# APM32F072 register map
File version: 1.0
Registers are 32-bit, read-write, reset 0x0 unless marked. A register's access mark holds for its fields unless they carry their own. Offsets are from the block's base; [hi:lo] are bit positions; {n}, {i} and the like mark numbered series.

## GPIOF — General-purpose I/Os
Base 0x48001400
Same registers: GPIOB 0x48000400, GPIOC 0x48000800, GPIOD 0x48000C00, GPIOE 0x48001000
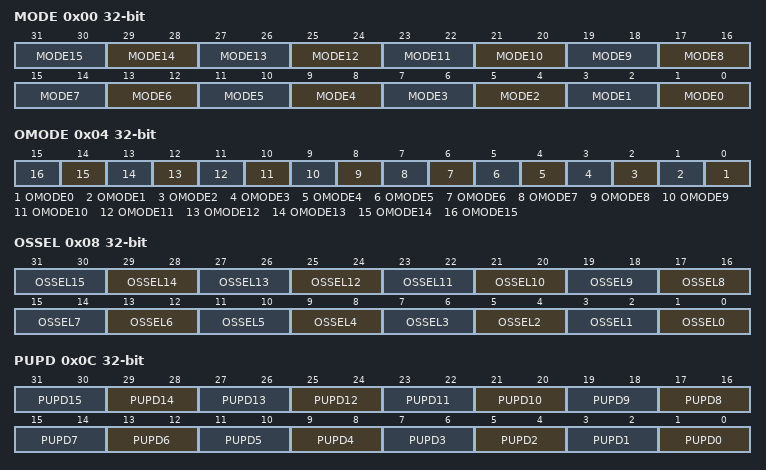
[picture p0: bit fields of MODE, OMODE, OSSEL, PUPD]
0x00 MODE — GPIO port mode register
  [2n+1:2n] MODE{n} (n=0..15) — Port x configuration bits (y = 0..15)
0x04 OMODE — GPIO port output type register
  [n] OMODE{n} (n=0..15) — Port x configuration bit {n}
0x08 OSSEL — GPIO port output speed register
  [2n+1:2n] OSSEL{n} (n=0..15) — Port x configuration bits (y = 0..15)
0x0C PUPD — GPIO port pull-up/pull-down register
  [2n+1:2n] PUPD{n} (n=0..15) — Port x configuration bits (y = 0..15)
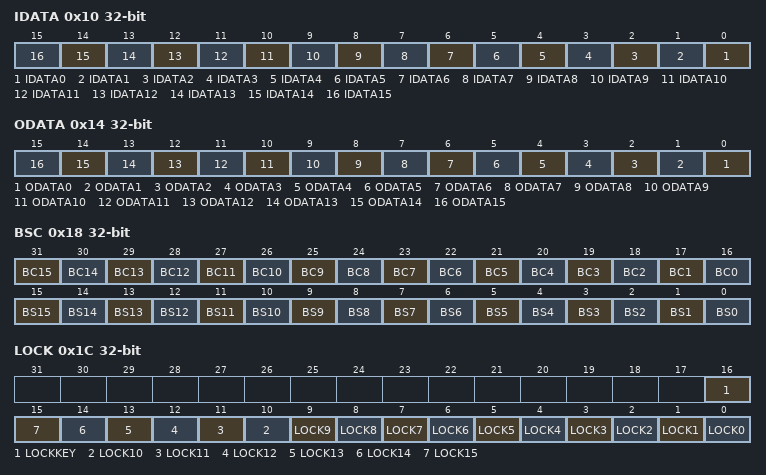
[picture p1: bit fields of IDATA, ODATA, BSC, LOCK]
0x10 IDATA ro — GPIO port input data register
  [n] IDATA{n} (n=0..15) — Port input data (y = 0..15)
0x14 ODATA — GPIO port output data register
  [n] ODATA{n} (n=0..15) — Port output data (y = 0..15)
0x18 BSC wo — GPIO port bit set/clear register
  [n+16] BC{n} (n=1..15) — Port x clear bit y (y = 0..15)
  [16] BC0 — Port x set bit y ( y = 0..15)
  [n] BS{n} (n=9..15) — Port x set bit y ( y = 0..15)
  [n] BS{n} (n=0..8) — Port x set bit y (y = 0..15)
0x1C LOCK — GPIO port configuration lock register
  [16] LOCKKEY — Port x lock bit y
  [n] LOCK{n} (n=0..15) — Port x lock bit y (y = 0..15)
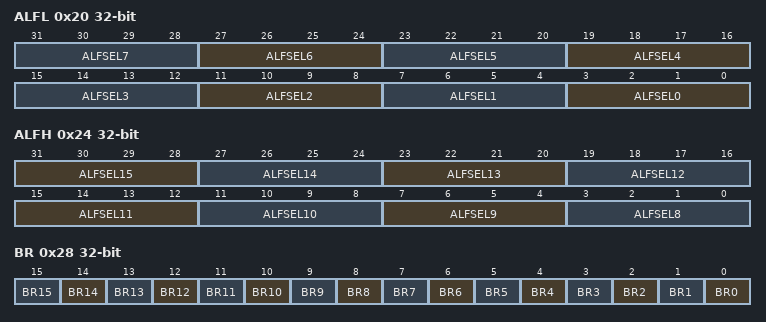
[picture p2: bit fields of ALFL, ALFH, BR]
0x20 ALFL — GPIO alternate function low register
  [4n+3:4n] ALFSEL{n} (n=0..7) — Alternate function selection for port xbit y (y = 0..7)
0x24 ALFH — GPIO alternate function high register
  [4n-29:4n-32] ALFSEL{n} (n=11..15) — Alternate function selection for port xbit y (y = 8..15)
  [11:8] ALFSEL10 — Alternate function selection for port x bit y (y = 8..15)
  [7:4] ALFSEL9 — Alternate function selection for port x bit y (y = 8..15)
  [3:0] ALFSEL8 — Alternate function selection for port x bit y (y = 8..15)
0x28 BR wo — Port bit clear register
  [n] BR{n} (n=0..15) — Port x clear bit y

## GPIOA — General-purpose I/Os
Base 0x48000000
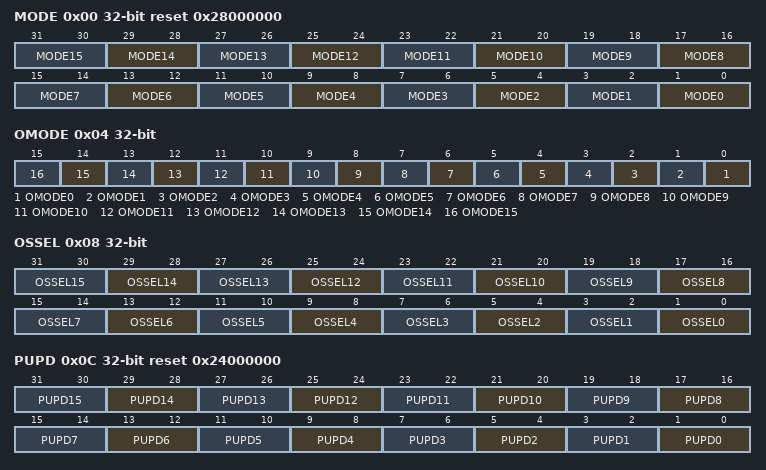
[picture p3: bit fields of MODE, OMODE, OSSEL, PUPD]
0x00 MODE reset 0x28000000 — GPIO port mode register
  [2n+1:2n] MODE{n} (n=0..15) — Port x configuration bits (y = 0..15)
0x04 OMODE — GPIO port output type register
  [n] OMODE{n} (n=0..15) — Port x configuration bits (y = 0..15)
0x08 OSSEL — GPIO port output speed register
  [2n+1:2n] OSSEL{n} (n=0..15) — Port x configuration bits (y = 0..15)
0x0C PUPD reset 0x24000000 — GPIO port pull-up/pull-down register
  [2n+1:2n] PUPD{n} (n=0..15) — Port x configuration bits (y = 0..15)
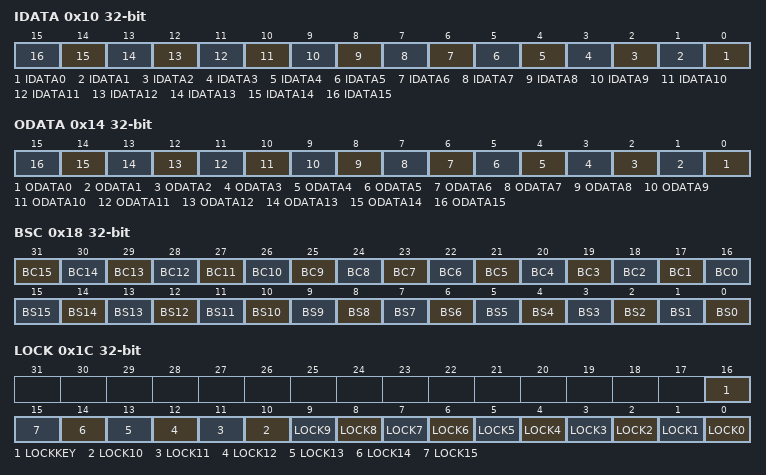
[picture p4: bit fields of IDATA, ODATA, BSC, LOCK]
0x10 IDATA ro — GPIO port input data register
  [n] IDATA{n} (n=0..15) — Port input data (y = 0..15)
0x14 ODATA — GPIO port output data register
  [n] ODATA{n} (n=0..15) — Port output data (y = 0..15)
0x18 BSC wo — GPIO port bit set/clear register
  [n+16] BC{n} (n=1..15) — Port x clear bit y (y = 0..15)
  [16] BC0 — Port x set bit y (y = 0..15)
  [n] BS{n} (n=0..15) — Port x set bit y (y = 0..15)
0x1C LOCK — GPIO port configuration lock register
  [16] LOCKKEY — Port x lock bit y (y = 0..15)
  [n] LOCK{n} (n=1..15) — Port x lock bit y (y = 0..15)
  [0] LOCK0 — Port x lock bit y (y = 0..15))
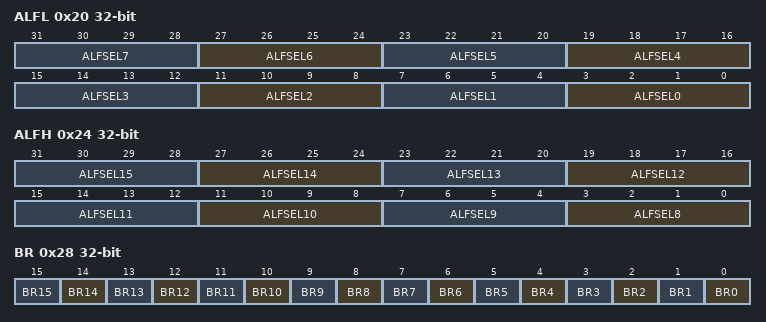
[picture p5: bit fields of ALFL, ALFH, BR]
0x20 ALFL — GPIO alternate function low register
  [4n+3:4n] ALFSEL{n} (n=0..7) — Alternate function selection for port x bit y (y = 0..7)
0x24 ALFH — GPIO alternate function high register
  [4n-29:4n-32] ALFSEL{n} (n=8..15) — Alternate function selection for port x bit y (y = 8..15)
0x28 BR wo — Port bit clear register
  [n] BR{n} (n=0..15) — Port x clear bit y

## SPI1 — Serial peripheral interface
Base 0x40013000
Same registers: SPI2 0x40003800
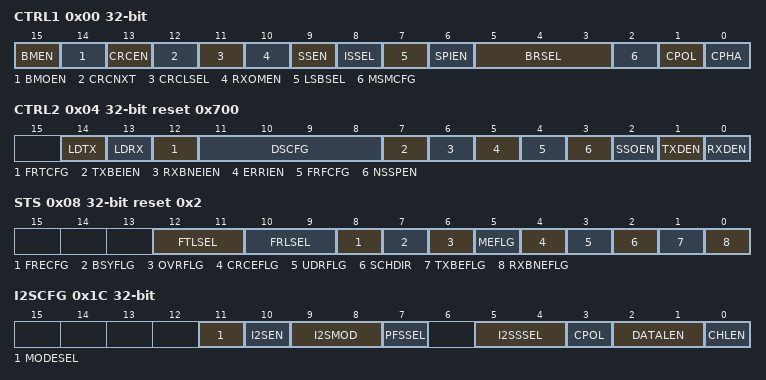
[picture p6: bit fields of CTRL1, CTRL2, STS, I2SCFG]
0x00 CTRL1 — control register 1
  [15] BMEN — Bidirectional data mode enable
  [14] BMOEN — Output enable in bidirectional mode
  [13] CRCEN — Hardware CRC calculation enable
  [12] CRCNXT — CRC transfer next
  [11] CRCLSEL — CRC length
  [10] RXOMEN — Receive only
  [9] SSEN — Software slave management
  [8] ISSEL — Internal slave select
  [7] LSBSEL — Frame format
  [6] SPIEN — SPI enable
  [5:3] BRSEL — Baud rate control
  [2] MSMCFG — Master selection
  [1] CPOL — Clock polarity
  [0] CPHA — Clock phase
0x04 CTRL2 reset 0x700 — control register 2
  [14] LDTX — Last DMA transfer for transmission
  [13] LDRX — Last DMA transfer for reception
  [12] FRTCFG — FIFO reception threshold
  [11:8] DSCFG — Data size
  [7] TXBEIEN — Tx buffer empty interrupt enable
  [6] RXBNEIEN — RX buffer not empty interrupt enable
  [5] ERRIEN — Error interrupt enable
  [4] FRFCFG — Frame format
  [3] NSSPEN — NSS pulse management
  [2] SSOEN — SS output enable
  [1] TXDEN — Tx buffer DMA enable
  [0] RXDEN — Rx buffer DMA enable
0x08 STS access per field reset 0x2 — status register
  [12:11] FTLSEL ro — FIFO transmission level
  [10:9] FRLSEL ro — FIFO reception level
  [8] FRECFG ro — TI frame format error
  [7] BSYFLG ro — Busy flag
  [6] OVRFLG ro — Overrun flag
  [5] MEFLG ro — Mode fault
  [4] CRCEFLG rw — CRC error flag
  [3] UDRFLG ro — Underrun flag
  [2] SCHDIR ro — Channel direction
  [1] TXBEFLG ro — Transmit buffer empty
  [0] RXBNEFLG ro — Receive buffer not empty
0x0C DATA
  [15:0] DATA
0x10 CRCPOLY reset 0x7 — CRC polynomial register
  [15:0] CRCPOLY
0x14 RXCRC ro
  [15:0] RXCRC
0x18 TXCRC ro
  [15:0] TXCRC
0x1C I2SCFG — I2S configuration register
  [11] MODESEL — I2S mode selection
  [10] I2SEN — I2S enable
  [9:8] I2SMOD — I2S configuration mode
  [7] PFSSEL — PCM frame synchronization
  [5:4] I2SSSEL — I2S standard selection
  [3] CPOL — Inactive state clock polarity
  [2:1] DATALEN — Data length to be transferred
  [0] CHLEN — Channel length
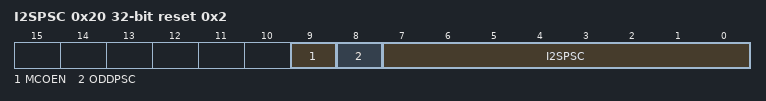
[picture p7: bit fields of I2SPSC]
0x20 I2SPSC reset 0x2 — I2S prescaler register
  [9] MCOEN — Master clock output enable
  [8] ODDPSC — Odd prescaler
  [7:0] I2SPSC — I2S prescaler
